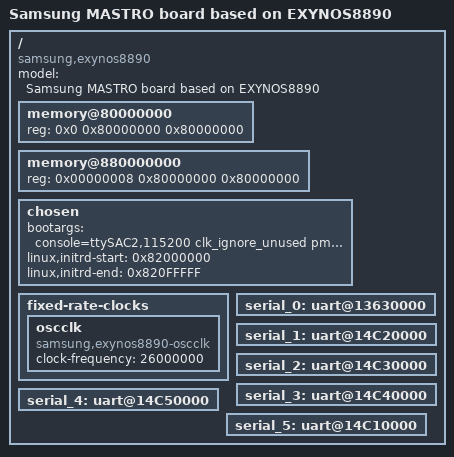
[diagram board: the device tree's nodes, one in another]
/*
 * SAMSUNG EXYNOS8890 board device tree source
 *
 * Copyright (c) 2016 Samsung Electronics Co., Ltd.
 *		http://www.samsung.com
 *
 * This program is free software; you can redistribute it and/or modify
 * it under the terms of the GNU General Public License version 2 as
 * published by the Free Software Foundation.
*/

/dts-v1/;
#include "exynos8890.dtsi"

/ {
	model = "Samsung MASTRO board based on EXYNOS8890";
	compatible = "samsung,exynos8890", "samsung,MAESTRO";

	memory@80000000 {
		device_type = "memory";
		reg = <0x0 0x80000000 0x80000000>;
	};

	memory@880000000 {
		device_type = "memory";
		reg = <0x00000008 0x80000000 0x80000000>;
	};

	chosen {
		bootargs = "console=ttySAC2,115200 clk_ignore_unused pmic_info=3 androidboot.hardware=samsungexynos8890 androidboot.selinux=permissive ess_setup=0x86000000";
		linux,initrd-start = <0x82000000>;
		linux,initrd-end = <0x820FFFFF>;
	};

	fixed-rate-clocks {
		oscclk {
			compatible = "samsung,exynos8890-oscclk";
			clock-frequency = <26000000>;
		};
	};

	serial_0: uart@13630000 {
		status = "okay";
	};

	serial_1: uart@14C20000 {
		status = "okay";
	};

	serial_2: uart@14C30000 {
		status = "okay";
	};

	serial_3: uart@14C40000 {
		status = "okay";
	};

	serial_4: uart@14C50000 {
		status = "okay";
	};

	serial_5: uart@14C10000 {
		status = "okay";
	};
};
